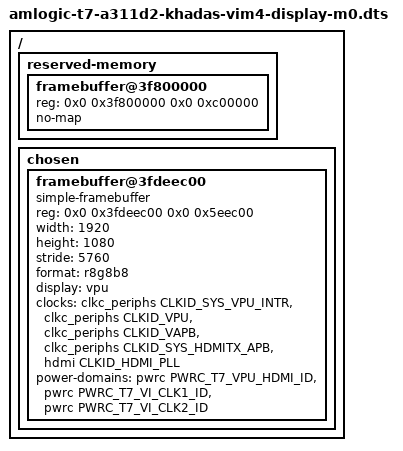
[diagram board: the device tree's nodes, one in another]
// SPDX-License-Identifier: (GPL-2.0+ OR MIT)
/* Experimental handoff for pd-handoff U-Boot, HDMI connected, no MIPI panel. */
#include "amlogic-t7-a311d2-khadas-vim4-audio-test.dts"

/ {
	reserved-memory {
		/*
		 * U-Boot's dual-logo command allocates two 1920x1080 RGB888
		 * frames here. Reserve both, including the unused VPP1 frame,
		 * before memblock chooses the command-line CMA allocation.
		 */
		framebuffer@3f800000 {
			reg = <0x0 0x3f800000 0x0 0xc00000>;
			no-map;
		};
	};

	chosen {
		#address-cells = <2>;
		#size-cells = <2>;
		ranges;

		/*
		 * OSD1 is the second frame: 0x3f800000 + 1920*1080*3.
		 * The scaler changes the output size, not this memory layout.
		 * This static handoff requires the matching bootloader setup;
		 * it is not suitable for a MIPI panel or arbitrary U-Boot env.
		 */
		framebuffer@3fdeec00 {
			compatible = "simple-framebuffer";
			reg = <0x0 0x3fdeec00 0x0 0x5eec00>;
			width = <1920>;
			height = <1080>;
			stride = <5760>;
			format = "r8g8b8";
			display = <&vpu>;
			clocks = <&clkc_periphs CLKID_SYS_VPU_INTR>,
				 <&clkc_periphs CLKID_VPU>,
				 <&clkc_periphs CLKID_VAPB>,
				 <&clkc_periphs CLKID_SYS_HDMITX_APB>,
				 <&hdmi CLKID_HDMI_PLL>;
			power-domains = <&pwrc PWRC_T7_VPU_HDMI_ID>,
					<&pwrc PWRC_T7_VI_CLK1_ID>,
					<&pwrc PWRC_T7_VI_CLK2_ID>;
		};
	};
};
